# bao1x register map
Vendor: baochip; File version: 1.0
Registers are 32-bit, read-write, reset 0x0 unless marked. A register's access mark holds for its fields unless they carry their own. Offsets are from the block's base; [hi:lo] are bit positions; 'fields as' and 'values as' point back to an identical list; <NAME> marks a mode.

## MBOX_APB
Base 0x40013000
0x00 SFR_WDATA — See `mbox_v0.1.sv#L105 <https://github.com/baochip/baochip-1x/blob/main/rtl/modu les/vexriscv/lib/mbox_v0.1.sv#L105>`__ (line numbers are approximate)
  [31:0] sfr_wdata — sfr_wdata read/write control register
0x04 SFR_RDATA — See `mbox_v0.1.sv#L106 <https://github.com/baochip/baochip-1x/blob/main/rtl/modu les/vexriscv/lib/mbox_v0.1.sv#L106>`__ (line numbers are approximate)
  [31:0] sfr_rdata — sfr_rdata read only status register
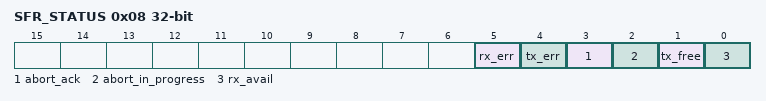
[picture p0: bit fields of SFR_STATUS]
0x08 SFR_STATUS — See `mbox_v0.1.sv#L107 <https://github.com/baochip/baochip-1x/blob/main/rtl/modu les/vexriscv/lib/mbox_v0.1.sv#L107>`__ (line numbers are approximate)
  [5] rx_err — rx_err read only status register
  [4] tx_err — tx_err read only status register
  [3] abort_ack — abort_ack read only status register
  [2] abort_in_progress — abort_in_progress read only status register
  [1] tx_free — tx_free read only status register
  [0] rx_avail — rx_avail read only status register
0x18 SFR_ABORT — See `mbox_v0.1.sv#L108 <https://github.com/baochip/baochip-1x/blob/main/rtl/modu les/vexriscv/lib/mbox_v0.1.sv#L108>`__ (line numbers are approximate)
  [31:0] sfr_abort — sfr_abort performs action on write of value: 0x1
0x1C SFR_DONE — See `mbox_v0.1.sv#L109 <https://github.com/baochip/baochip-1x/blob/main/rtl/modu les/vexriscv/lib/mbox_v0.1.sv#L109>`__ (line numbers are approximate)
  [31:0] sfr_done — sfr_done performs action on write of value: 0x1

## RRC
Base 0x40000000
0x00 SFR_RRCCR — See `rrc.sv#L261 <https://github.com/baochip/baochip-1x/blob/main/rtl/modules/rr c/rtl/rrc.sv#L261>`__ (line numbers are approximate)
  [31:0] sfr_rrccr — sfr_rrccr read/write control register
0x04 SFR_RRCFD — See `rrc.sv#L262 <https://github.com/baochip/baochip-1x/blob/main/rtl/modules/rr c/rtl/rrc.sv#L262>`__ (line numbers are approximate)
  [4:0] sfr_rrcfd — sfr_rrcfd read/write control register
0x08 SFR_RRCSR — See `rrc.sv#L263 <https://github.com/baochip/baochip-1x/blob/main/rtl/modules/rr c/rtl/rrc.sv#L263>`__ (line numbers are approximate)
  [9:0] sfr_rrcsr — sfr_rrcsr read only status register
0x0C SFR_RRCFR — See `rrc.sv#L264 <https://github.com/baochip/baochip-1x/blob/main/rtl/modules/rr c/rtl/rrc.sv#L264>`__ (line numbers are approximate)
  [4:0] sfr_rrcfr — sfr_rrcfr flag register. `1` means event happened, write back `1` in respective bit position to clear the flag
0x14 SFR_RRCSR_SET0 — See `rrc.sv#L266 <https://github.com/baochip/baochip-1x/blob/main/rtl/modules/rr c/rtl/rrc.sv#L266>`__ (line numbers are approximate)
  [31:0] trc_set_failure — trc_set_failure read only status register
0x18 SFR_RRCSR_SET1 — See `rrc.sv#L267 <https://github.com/baochip/baochip-1x/blob/main/rtl/modules/rr c/rtl/rrc.sv#L267>`__ (line numbers are approximate)
  [31:0] trc_set_failure — trc_set_failure read only status register
0x1C SFR_RRCSR_RST0 — See `rrc.sv#L268 <https://github.com/baochip/baochip-1x/blob/main/rtl/modules/rr c/rtl/rrc.sv#L268>`__ (line numbers are approximate)
  [31:0] trc_reset_failure — trc_reset_failure read only status register
0x20 SFR_RRCSR_RST1 — See `rrc.sv#L269 <https://github.com/baochip/baochip-1x/blob/main/rtl/modules/rr c/rtl/rrc.sv#L269>`__ (line numbers are approximate)
  fields as SFR_RRCSR_RST0
0x24 SFR_RRCSR_RD0 — See `rrc.sv#L270 <https://github.com/baochip/baochip-1x/blob/main/rtl/modules/rr c/rtl/rrc.sv#L270>`__ (line numbers are approximate)
  [31:0] trc_fourth_read_failure — trc_fourth_read_failure read only status register
0x28 SFR_RRCSR_RD1 — See `rrc.sv#L271 <https://github.com/baochip/baochip-1x/blob/main/rtl/modules/rr c/rtl/rrc.sv#L271>`__ (line numbers are approximate)
  fields as SFR_RRCSR_RD0
0xF0 SFR_RRCAR — See `rrc.sv#L273 <https://github.com/baochip/baochip-1x/blob/main/rtl/modules/rr c/rtl/rrc.sv#L273>`__ (line numbers are approximate)
  [31:0] sfr_rrcar — sfr_rrcar performs action on write of value: 0x2468
